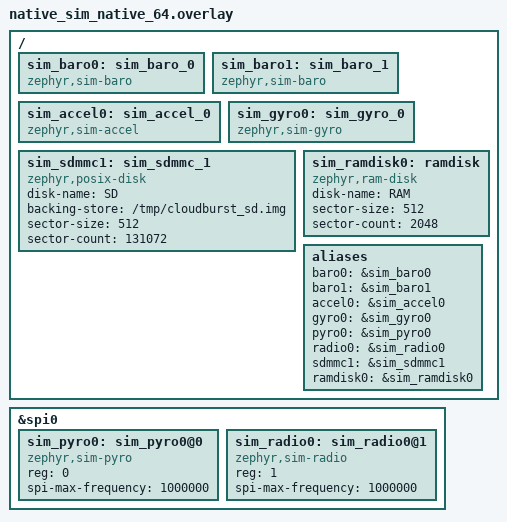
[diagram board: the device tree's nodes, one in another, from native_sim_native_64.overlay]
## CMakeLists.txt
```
# SPDX-License-Identifier: Apache-2.0

cmake_minimum_required(VERSION 3.20.0)

list(APPEND DTS_ROOT ${CMAKE_CURRENT_SOURCE_DIR})

set(BOARD_ROOT ${CMAKE_CURRENT_LIST_DIR}/..)

set(ZEPHYR_EXTRA_MODULES ${CMAKE_CURRENT_LIST_DIR}/..)

# Compatible boards for this app
set(COMPATIBLE_BOARDS
    ubcrocket_polarity
    native_sim/native/64
    native_sim
)

if(NOT BOARD IN_LIST COMPATIBLE_BOARDS)
    message(WARNING
        "Board '${BOARD}' is not listed as compatible with this application.\n"
        "Compatible boards: ${COMPATIBLE_BOARDS}\n"
        "Build may fail or behave unexpectedly.\n"
        "To add compatibility for this board, add it to the COMPATIBLE_BOARDS list in CMakeLists.txt.")
endif()

find_package(Zephyr REQUIRED HINTS $ENV{ZEPHYR_BASE})
project(cloudburst)

# Include nanopb for protobuf support
list(APPEND CMAKE_MODULE_PATH ${ZEPHYR_BASE}/modules/nanopb)
include(nanopb)

# Generate protobuf sources from falcon-protos
set(FALCON_PROTOS_DIR ${CMAKE_CURRENT_LIST_DIR}/../../modules/falcon-protos)
zephyr_nanopb_sources(app ${FALCON_PROTOS_DIR}/TelemetryPacket.proto)
zephyr_nanopb_sources(app ${FALCON_PROTOS_DIR}/GroundCommand.proto)

# LwGPS NMEA parser library
set(LWGPS_DIR ${CMAKE_CURRENT_LIST_DIR}/../../modules/lwgps)

target_sources(app PRIVATE
  src/main.c
  src/data.c
  src/sensors/imu_thread.c
  src/logger_thread.c
  src/sensors/baro_thread.c
  src/state_machine/state_machine.c
  src/state_machine/state_machine_common.c
  src/state_machine/states/standby.c
  src/state_machine/states/ascent.c
  src/state_machine/states/mach_lock.c
  src/state_machine/states/drogue_descent.c
  src/state_machine/states/main_descent.c
  src/state_machine/states/landed.c
  src/pyro/pyro_thread.c
  src/radio/radio_thread.c
  src/radio/gnss_spi.c
  src/radio/command_thread.c
  src/radio/rfd900x_at.c
  src/radio/rfd900x.c
  src/camera/vtx_power.c
  src/camera/runcam.c
  src/gps/gps_thread.c
  ${LWGPS_DIR}/lwgps/src/lwgps/lwgps.c
)

target_include_directories(app PRIVATE
  src
  src/state_machine
  src/gps
  ${LWGPS_DIR}/lwgps/src/include
)

if(DEFINED DATA_FILE)
  zephyr_compile_definitions(DATA_FILE="${DATA_FILE}")
endif()
```

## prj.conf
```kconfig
# Enable simulated sensors for native_sim
CONFIG_SIM_BARO=y
CONFIG_SIM_ACCEL=y
CONFIG_SIM_GYRO=y
CONFIG_SIM_PYRO=y
CONFIG_SIM_RADIO=y
CONFIG_SIM_SDMMC=y

# Enable GPIO support
CONFIG_GPIO=y

# Enable sensor subsystem
CONFIG_SENSOR=y

# Enable SPI support
CONFIG_SPI=y

# Enable C++ support
CONFIG_CPP=y

# Enable SMF (state machine framework)
CONFIG_SMF=y

# Enable BMI08X sensor driver
CONFIG_BMI08X=y
CONFIG_BMI08X_ACCEL_TRIGGER_NONE=y
CONFIG_BMI08X_GYRO_TRIGGER_NONE=y

# Enable MS5607 and MS5611 barometer drivers
CONFIG_MS5607=y
CONFIG_MS5611=y

# Enable SDMMC disk driver and hardware flow control
CONFIG_DISK_DRIVER_SDMMC=y
CONFIG_SDMMC_STM32_HWFC=y

# Enable disk access API
CONFIG_DISK_ACCESS=y

# Enable file system support
CONFIG_FILE_SYSTEM=y
CONFIG_FAT_FILESYSTEM_ELM=y
CONFIG_FS_FATFS_LFN=y

# Set main thread stack size
CONFIG_MAIN_STACK_SIZE=2048

# Enable sensor asynchronous API
CONFIG_SENSOR_ASYNC_API=y

# Enable debugging features (for development only)
CONFIG_PRINTK=y
CONFIG_CBPRINTF_FP_SUPPORT=y
CONFIG_LOG=y
CONFIG_LOG_MODE_IMMEDIATE=y
CONFIG_SENSOR_LOG_LEVEL_DBG=n
CONFIG_SPI_LOG_LEVEL_DBG=n
CONFIG_GPIO_LOG_LEVEL_DBG=n
CONFIG_BOOT_BANNER=y
CONFIG_ASSERT=n
CONFIG_DEBUG=y
CONFIG_NO_OPTIMIZATIONS=y

# Enable thread debugging features
CONFIG_DEBUG_THREAD_INFO=y
CONFIG_THREAD_MONITOR=y
CONFIG_THREAD_NAME=y
CONFIG_THREAD_STACK_INFO=n
CONFIG_STACK_SENTINEL=y

# Enable nanopb for protobuf support
CONFIG_NANOPB=y

# Enable CRC for packet integrity checking
CONFIG_CRC=y

# Enable COBS for packet framing
CONFIG_COBS=y
```

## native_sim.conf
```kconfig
# Disable embedded filesystems
CONFIG_FILE_SYSTEM_LITTLEFS=n
CONFIG_FILE_SYSTEM_FATFS=n

# Enable host filesystem
CONFIG_FILE_SYSTEM=y
CONFIG_FS_POSIX=y
CONFIG_POSIX_FS=y

# Enable simulated sensors for native_sim
CONFIG_SIM_BARO=y
CONFIG_SIM_ACCEL=y
CONFIG_SIM_GYRO=y
CONFIG_SIM_PYRO=y
CONFIG_SIM_SDMMC=y

# Enable fake sensors for native_sim
CONFIG_EMUL=y
CONFIG_SPI_EMUL=y
CONFIG_SENSOR_SHELL=y

# Enable the random number generator for native_sim
CONFIG_ENTROPY_GENERATOR=y

# Enable RAM disk driver for native_sim
CONFIG_DISK_DRIVER_RAM=y
```

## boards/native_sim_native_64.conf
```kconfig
CONFIG_FILE_SYSTEM=y
CONFIG_FILE_SYSTEM_SHELL=y

# Disable SD card specific features
CONFIG_FAT_FILESYSTEM_ELM=n
CONFIG_DISK_DRIVER_SDMMC=n

# Enable simulated sensors for native_sim
CONFIG_SIM_BARO=y
CONFIG_SIM_ACCEL=y
CONFIG_SIM_GYRO=y
CONFIG_SIM_PYRO=y
CONFIG_SIM_SDMMC=y

# Enable fake sensors for native_sim
CONFIG_EMUL=y
CONFIG_SPI_EMUL=y
CONFIG_SENSOR_SHELL=y

# Enable the random number generator for native_sim
CONFIG_ENTROPY_GENERATOR=y

# Enable RAM disk driver for native_sim
CONFIG_DISK_DRIVER_RAM=y
```

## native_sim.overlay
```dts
/ {
    sim_baro0: sim_baro_0 {
        compatible = "zephyr,sim-baro";
        status = "okay";
    };

    sim_baro1: sim_baro_1 {
        compatible = "zephyr,sim-baro";
        status = "okay";
    };

    sim_accel0: sim_accel_0 {
        compatible = "zephyr,sim-accel";
        status = "okay";
    };

    sim_gyro0: sim_gyro_0 {
        compatible = "zephyr,sim-gyro";
        status = "okay";
    };

    sim_sdmmc1: sim_sdmmc_1 {
        compatible = "zephyr,posix-disk";
        status = "okay";
        disk-name = "SD";
        backing-store = "/tmp/cloudburst_sd.img";
        sector-size = <512>;
        sector-count = <131072>; /* 64 MB */
    };

    sim_ramdisk0: ramdisk {
        compatible = "zephyr,ram-disk";
        disk-name = "RAM";
        sector-size = <512>;
        sector-count = <2048>; /* 1 MB */
    };

    aliases {
        baro0 = &sim_baro0;
        baro1 = &sim_baro1;
        accel0 = &sim_accel0;
        gyro0 = &sim_gyro0;
        pyro0 = &sim_pyro0;
        sdmmc1 = &sim_sdmmc1;
        ramdisk0 = &sim_ramdisk0;
    };
};

&spi0 {
    status = "okay";

    sim_pyro0: sim_pyro0@0 {
        compatible = "zephyr,sim-pyro";
        reg = <0>;
        spi-max-frequency = <1000000>;
        status = "okay";
    };
};
```

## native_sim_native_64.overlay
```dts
/ {
    sim_baro0: sim_baro_0 {
        compatible = "zephyr,sim-baro";
        status = "okay";
    };

    sim_baro1: sim_baro_1 {
        compatible = "zephyr,sim-baro";
        status = "okay";
    };

    sim_accel0: sim_accel_0 {
        compatible = "zephyr,sim-accel";
        status = "okay";
    };

    sim_gyro0: sim_gyro_0 {
        compatible = "zephyr,sim-gyro";
        status = "okay";
    };

    sim_sdmmc1: sim_sdmmc_1 {
        compatible = "zephyr,posix-disk";
        status = "okay";
        disk-name = "SD";
        backing-store = "/tmp/cloudburst_sd.img";
        sector-size = <512>;
        sector-count = <131072>; /* 64 MB */
    };

    sim_ramdisk0: ramdisk {
        compatible = "zephyr,ram-disk";
        disk-name = "RAM";
        sector-size = <512>;
        sector-count = <2048>; /* 1 MB */
    };

    aliases {
        baro0 = &sim_baro0;
        baro1 = &sim_baro1;
        accel0 = &sim_accel0;
        gyro0 = &sim_gyro0;
        pyro0 = &sim_pyro0;
        radio0 = &sim_radio0;
        sdmmc1 = &sim_sdmmc1;
        ramdisk0 = &sim_ramdisk0;
    };
};

&spi0 {
    status = "okay";

    sim_pyro0: sim_pyro0@0 {
        compatible = "zephyr,sim-pyro";
        reg = <0>;
        spi-max-frequency = <1000000>;
        status = "okay";
    };

    sim_radio0: sim_radio0@1 {
        compatible = "zephyr,sim-radio";
        reg = <1>;
        spi-max-frequency = <1000000>;
        status = "okay";
    };
};
```

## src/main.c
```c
#include <zephyr/kernel.h>
#include <zephyr/device.h>
#include <zephyr/devicetree.h>
#include <zephyr/drivers/sensor.h>
#include <zephyr/logging/log.h>
#include "sensors/imu_thread.h"
#include "sensors/baro_thread.h"
#include "logger_thread.h"
#include "state_machine/state_machine.h"
#include "pyro/pyro_thread.h"
#include "radio/radio_thread.h"
#include "radio/command_thread.h"
#include "gps/gps_thread.h"
#include "data.h"

LOG_MODULE_REGISTER(falcon_main, LOG_LEVEL_INF);

int main(void)
{
    LOG_INF("Falcon application started");

    // Start the threads
    start_imu_thread();
    start_logger_thread();
    start_baro_thread();
    start_pyro_thread();
    start_state_machine_thread();
    start_radio_thread();
    start_gps_thread();
    start_command_threads();

    return 0;
}
```

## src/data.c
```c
#include <zephyr/kernel.h>
#include <zephyr/logging/log.h>
#include "data.h"

LOG_MODULE_REGISTER(data, LOG_LEVEL_INF);

// Global instances
struct imu_data g_imu_data;
struct baro_data g_baro_data;
struct state_data g_state_data;
struct pyro_data g_pyro_data;
struct gps_data g_gps_data;
struct camera_data g_camera_data;

// Mutexes for thread safety
K_MUTEX_DEFINE(imu_mutex);
K_MUTEX_DEFINE(baro_mutex);
K_MUTEX_DEFINE(state_mutex);
K_MUTEX_DEFINE(pyro_data_mutex);
K_MUTEX_DEFINE(gps_mutex);
K_MUTEX_DEFINE(camera_mutex);

// Setter functions
void set_imu_data(const struct imu_data *src)
{
    k_mutex_lock(&imu_mutex, K_FOREVER);
    g_imu_data = *src;
    k_mutex_unlock(&imu_mutex);
}

void set_baro_data(const struct baro_data *src)
{
    k_mutex_lock(&baro_mutex, K_FOREVER);
    g_baro_data = *src;
    k_mutex_unlock(&baro_mutex);
}

// Getter functions
void get_imu_data(struct imu_data *dst)
{
    k_mutex_lock(&imu_mutex, K_FOREVER);
    *dst = g_imu_data;
    k_mutex_unlock(&imu_mutex);
}

void get_baro_data(struct baro_data *dst)
{
    k_mutex_lock(&baro_mutex, K_FOREVER);
    *dst = g_baro_data;
    k_mutex_unlock(&baro_mutex);
}

void set_state_data(const struct state_data *src)
{
    k_mutex_lock(&state_mutex, K_FOREVER);
    g_state_data = *src;
    k_mutex_unlock(&state_mutex);
}

void get_state_data(struct state_data *dst)
{
    k_mutex_lock(&state_mutex, K_FOREVER);
    *dst = g_state_data;
    k_mutex_unlock(&state_mutex);
}

void set_pyro_data(const struct pyro_data *src)
{
    k_mutex_lock(&pyro_data_mutex, K_FOREVER);

    // Log changes to pyro flags
    if (src->drogue_fire_requested != g_pyro_data.drogue_fire_requested) {
        LOG_INF("Pyro: drogue_fire_requested -> %d", src->drogue_fire_requested);
    }
    if (src->main_fire_requested != g_pyro_data.main_fire_requested) {
        LOG_INF("Pyro: main_fire_requested -> %d", src->main_fire_requested);
    }
    if (src->drogue_fire_ack != g_pyro_data.drogue_fire_ack) {
        LOG_INF("Pyro: drogue_fire_ack -> %d", src->drogue_fire_ack);
    }
    if (src->main_fire_ack != g_pyro_data.main_fire_ack) {
        LOG_INF("Pyro: main_fire_ack -> %d", src->main_fire_ack);
    }
    if (src->drogue_fired != g_pyro_data.drogue_fired) {
        LOG_INF("Pyro: drogue_fired -> %d", src->drogue_fired);
    }
    if (src->main_fired != g_pyro_data.main_fired) {
        LOG_INF("Pyro: main_fired -> %d", src->main_fired);
    }
    if (src->drogue_fail != g_pyro_data.drogue_fail) {
        LOG_ERR("Pyro: drogue_fail -> %d", src->drogue_fail);
    }
    if (src->main_fail != g_pyro_data.main_fail) {
        LOG_ERR("Pyro: main_fail -> %d", src->main_fail);
    }
    if (src->drogue_cont_ok != g_pyro_data.drogue_cont_ok) {
        LOG_INF("Pyro: drogue_cont_ok -> %d", src->drogue_cont_ok);
    }
    if (src->main_cont_ok != g_pyro_data.main_cont_ok) {
        LOG_INF("Pyro: main_cont_ok -> %d", src->main_cont_ok);
    }

    g_pyro_data = *src;
    k_mutex_unlock(&pyro_data_mutex);
}

void get_pyro_data(struct pyro_data *dst)
{
    k_mutex_lock(&pyro_data_mutex, K_FOREVER);
    *dst = g_pyro_data;
    k_mutex_unlock(&pyro_data_mutex);
}

void set_gps_data(const struct gps_data *src)
{
    k_mutex_lock(&gps_mutex, K_FOREVER);
    g_gps_data = *src;
    k_mutex_unlock(&gps_mutex);
}

void get_gps_data(struct gps_data *dst)
{
    k_mutex_lock(&gps_mutex, K_FOREVER);
    *dst = g_gps_data;
    k_mutex_unlock(&gps_mutex);
}

void set_camera_data(const struct camera_data *src)
{
    k_mutex_lock(&camera_mutex, K_FOREVER);

    if (src->vtx_power_on != g_camera_data.vtx_power_on) {
        LOG_INF("Camera: vtx_power_on -> %d", src->vtx_power_on);
    }
    if (src->recording != g_camera_data.recording) {
        LOG_INF("Camera: recording -> %d", src->recording);
    }

    g_camera_data = *src;
    k_mutex_unlock(&camera_mutex);
}

void get_camera_data(struct camera_data *dst)
{
    k_mutex_lock(&camera_mutex, K_FOREVER);
    *dst = g_camera_data;
    k_mutex_unlock(&camera_mutex);
}
```

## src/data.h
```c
#ifndef DATA_H
#define DATA_H

#include <stdint.h>
#include <stdbool.h>

typedef enum {
    FLIGHT_STATE_STANDBY = 0,
    FLIGHT_STATE_ASCENT,
    FLIGHT_STATE_MACH_LOCK,
    FLIGHT_STATE_DROGUE_DESCENT,
    FLIGHT_STATE_MAIN_DESCENT,
    FLIGHT_STATE_LANDED,
} flight_state_id_t;

// Data structures for sensor data
struct imu_data {
    float accel[3];    // Acceleration in m/s²
    float gyro[3];     // Angular velocity in rad/s
    int64_t timestamp; // Timestamp in milliseconds
};

// Per-barometer sensor data
struct baro_sensor_data {
    float pressure;    // Pressure in Pa
    float temperature; // Temperature in °C
    float altitude;    // Altitude in meters (from pressure + temp)
    float nis;         // Normalized innovation squared
    uint8_t faults;    // Accumulated fault count
    bool healthy;      // Health status (accepted/rejected)
};

// Combined barometer data (shared with other threads)
struct baro_data {
    struct baro_sensor_data baro0; // Barometer 0
    struct baro_sensor_data baro1; // Barometer 1

    float altitude;     // Kalman-filtered altitude estimate in meters (absolute)
    float altitude_agl; // Kalman-filtered altitude AGL (relative to ground) in meters
    float alt_variance; // Kalman filter variance (P)
    float velocity;     // Vertical velocity estimate (m/s)
    float vel_variance; // Velocity variance (P11)

    int64_t timestamp; // Timestamp in milliseconds
};

struct state_data {
    flight_state_id_t state;
    float ground_altitude;
    bool ground_calibrated;
    int64_t timestamp;
};

struct pyro_data {
    uint8_t status_byte;
    int64_t timestamp;
    bool drogue_fired;
    bool main_fired;
    bool drogue_fail;
    bool main_fail;
    bool drogue_cont_ok;
    bool main_cont_ok;
    bool drogue_fire_ack;
    bool main_fire_ack;
    bool drogue_fire_requested;
    bool main_fire_requested;
};

struct gps_data {
    float latitude;   // Degrees
    float longitude;  // Degrees
    float altitude;   // Altitude in meters
    float speed;      // Speed in knots
    uint8_t sats;     // Satellites in use
    uint8_t fix;      // Fix quality
    int64_t timestamp;
};

// VTX/RunCam status (shared between command executor, state machine and radio)
struct camera_data {
    bool vtx_power_on; // VTX/RunCam power switch state
    bool recording;    // RunCam recording state (optimistic, no protocol ack)
    int64_t timestamp;
};

// Global instances
extern struct imu_data g_imu_data;
extern struct baro_data g_baro_data;
extern struct state_data g_state_data;
extern struct pyro_data g_pyro_data;
extern struct gps_data g_gps_data;
extern struct camera_data g_camera_data;

// Getters and setters
void set_imu_data(const struct imu_data *src);
void get_imu_data(struct imu_data *dst);

void set_baro_data(const struct baro_data *src);
void get_baro_data(struct baro_data *dst);

void set_state_data(const struct state_data *src);
void get_state_data(struct state_data *dst);

void set_pyro_data(const struct pyro_data *src);
void get_pyro_data(struct pyro_data *dst);

void set_gps_data(const struct gps_data *src);
void get_gps_data(struct gps_data *dst);

void set_camera_data(const struct camera_data *src);
void get_camera_data(struct camera_data *dst);

#endif
```

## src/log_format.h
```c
#ifndef LOG_FORMAT_H
#define LOG_FORMAT_H

#include "data.h"
#include <stdint.h>

struct log_frame {
    int64_t log_timestamp;

    struct imu_data imu;
    struct baro_data baro;
    struct state_data state;
    struct pyro_data pyro;
    struct gps_data gps;
};

#endif
```

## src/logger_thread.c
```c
#include <zephyr/kernel.h>
#include <zephyr/sys/printk.h>
#include <zephyr/logging/log.h>
#include <zephyr/device.h>
#include <stdio.h>
#include <string.h>
#include "data.h"
#include "log_format.h"

#ifndef CONFIG_BOARD_NATIVE_SIM
#include <zephyr/storage/disk_access.h>
#include <zephyr/fs/fs.h>
#include <ff.h>
#endif

LOG_MODULE_REGISTER(logger_thread, LOG_LEVEL_INF);

#define LOGGER_THREAD_STACK_SIZE 2048
#define LOGGER_THREAD_PRIORITY 7
#define LOGGER_THREAD_PERIOD_MS 50
#define LOGGER_SYNC_PERIOD_MS 500

#ifdef CONFIG_BOARD_NATIVE_SIM
// Use standard POSIX file I/O for native_sim
#include <unistd.h>
#include <fcntl.h>
#include <dirent.h>
#include <sys/stat.h>

#define MOUNT_POINT "/tmp/zephyr_logs"
static FILE *log_file_ptr = NULL;

#else
// Use Zephyr FS API for real hardware
#define SDMMC_NODE DT_ALIAS(sdmmc1)
#define DISK_DRIVE_NAME DT_PROP(SDMMC_NODE, disk_name)
#define MOUNT_POINT "/" DISK_DRIVE_NAME ":"

static FATFS fat_fs;
static struct fs_mount_t fatfs_mnt = {
    .type = FS_FATFS, .mnt_point = MOUNT_POINT, .fs_data = &fat_fs};

static struct fs_file_t log_file;
#endif

K_THREAD_STACK_DEFINE(logger_stack, LOGGER_THREAD_STACK_SIZE);
static struct k_thread logger_thread;

static char log_file_name[128];

static int mount_filesystem(void)
{
#ifdef CONFIG_BOARD_NATIVE_SIM
    // Create directory if it doesn't exist
    struct stat st = {0};
    if (stat(MOUNT_POINT, &st) == -1) {
        mkdir(MOUNT_POINT, 0755);
    }
    LOG_INF("Using POSIX filesystem at %s", MOUNT_POINT);
    return 0;
#else
    int ret;

    // Initialize the SDMMC disk
    ret = disk_access_ioctl(DISK_DRIVE_NAME, DISK_IOCTL_CTRL_INIT, NULL);
    if (ret < 0) {
        LOG_ERR("Disk access initialization failed: %d", ret);
        return ret;
    }

    // Mount the FATFS file system
    ret = fs_mount(&fatfs_mnt);
    if (ret == 0) {
        LOG_INF("File system mounted at %s", MOUNT_POINT);
    } else {
        LOG_ERR("File system mount failed: %d", ret);
    }
    return ret;
#endif
}

static int write_csv_header(void)
{
    const char *header = "Log_Timestamp(ms),"
                         "IMU_Timestamp(ms),Accel_X(m/s^2),Accel_Y(m/s^2),Accel_Z(m/s^2),"
                         "Gyro_X(rad/s),Gyro_Y(rad/s),Gyro_Z(rad/s),"
                         "Baro_Timestamp(ms),"
                         "Baro0_Pressure(Pa),Baro0_Temperature(C),Baro0_Altitude(m),Baro0_NIS,"
                         "Baro0_Faults,Baro0_Healthy,"
                         "Baro1_Pressure(Pa),Baro1_Temperature(C),Baro1_Altitude(m),Baro1_NIS,"
                         "Baro1_Faults,Baro1_Healthy,"
                         "KF_Altitude(m),KF_Altitude_AGL(m),KF_AltVar,KF_Velocity(m/s),KF_VelVar,"
                         "State,State_Ground_Altitude(m),State_Timestamp(ms),"
                         "Pyro_Status,Pyro_Timestamp(ms),"
                         "Drogue_Fired,Main_Fired,Drogue_Fail,Main_Fail,"
                         "Drogue_Cont_OK,Main_Cont_OK,Drogue_Fire_ACK,Main_Fire_ACK,"
                         "Drogue_Fire_Requested,Main_Fire_Requested,"
                         "GPS_Timestamp(ms),GPS_Lat(deg),GPS_Lon(deg),"
                         "GPS_Alt(m),GPS_Speed(kn),GPS_Sats,GPS_Fix\n";
#ifdef CONFIG_BOARD_NATIVE_SIM
    size_t written = fwrite(header, 1, strlen(header), log_file_ptr);
    if (written != strlen(header)) {
        LOG_ERR("Failed to write header");
        return -1;
    }
    fflush(log_file_ptr);
    return 0;
#else
    int ret = fs_write(&log_file, header, strlen(header));
    if (ret < 0) {
        LOG_ERR("Failed to write header to log file: %d", ret);
        return ret;
    }

    ret = fs_sync(&log_file);
    if (ret < 0) {
        LOG_ERR("Failed to sync log file after writing header: %d", ret);
        return ret;
    }
    return 0;
#endif
}

static int create_new_log_file(void)
{
    int file_count = 0;

#ifdef CONFIG_BOARD_NATIVE_SIM
    DIR *dir = opendir(MOUNT_POINT);
    if (dir) {
        struct dirent *entry;
        struct stat st;
        char filepath[256];

        while ((entry = readdir(dir)) != NULL) {
            // Skip "." and ".." entries
            if (strcmp(entry->d_name, ".") == 0 || strcmp(entry->d_name, "..") == 0) {
                continue;
            }

            // Build full path and check if it's a regular file
            snprintf(filepath, sizeof(filepath), "%s/%s", MOUNT_POINT, entry->d_name);
            if (stat(filepath, &st) == 0 && S_ISREG(st.st_mode)) {
                file_count++;
            }
        }
        closedir(dir);
    }

    snprintf(log_file_name, sizeof(log_file_name), "%s/log_%d.csv", MOUNT_POINT, file_count);

    log_file_ptr = fopen(log_file_name, "w");
    if (!log_file_ptr) {
        LOG_ERR("Failed to open log file: %s", log_file_name);
        return -1;
    }

    LOG_INF("Log file created: %s", log_file_name);
#else
    int ret;
    struct fs_dir_t dir;
    struct fs_dirent entry;

    fs_dir_t_init(&dir);
    ret = fs_opendir(&dir, MOUNT_POINT);
    if (ret < 0) {
        LOG_ERR("Failed to open directory: %d", ret);
        return ret;
    }

    while (fs_readdir(&dir, &entry) == 0 && entry.name[0] != '\0') {
        if (entry.type == FS_DIR_ENTRY_FILE) {
            file_count++;
        }
    }
    fs_closedir(&dir);

    snprintf(log_file_name, sizeof(log_file_name), MOUNT_POINT "/log_%d.csv", file_count);

    fs_file_t_init(&log_file);
    ret = fs_open(&log_file, log_file_name, FS_O_CREATE | FS_O_APPEND | FS_O_WRITE);
    if (ret < 0) {
        LOG_ERR("Failed to open log file: %d", ret);
        return ret;
    }

    LOG_INF("Log file created: %s", log_file_name);
#endif

    return write_csv_header();
}

static int format_log_entry(const struct log_frame *frame, char *buffer, size_t buffer_size)
{
    return snprintf(
        buffer, buffer_size,
        "%lld,%lld,%.3f,%.3f,%.3f,%.3f,%.3f,%.3f,%lld," // Log_Timestamp, IMU_Timestamp,
                                                        // Accel_X/Y/Z, Gyro_X/Y/Z, Baro_Timestamp
        "%.3f,%.3f,%.3f,%.3f,%u,%d," // Baro0_Pressure, Baro0_Temperature, Baro0_Altitude,
                                     // Baro0_NIS, Baro0_Faults, Baro0_Healthy
        "%.3f,%.3f,%.3f,%.3f,%u,%d," // Baro1_Pressure, Baro1_Temperature, Baro1_Altitude,
                                     // Baro1_NIS, Baro1_Faults, Baro1_Healthy
        "%.3f,%.3f,%.3f,%.3f,%.3f,%d,%.3f,%lld," // KF_Altitude, KF_Altitude_AGL, KF_AltVar,
                                                 // KF_Velocity, KF_VelVar, State,
                                                 // State_Ground_Altitude, State_Timestamp
        "%u,%lld,%d,%d,%d,%d,%d,%d,%d,%d,%d,%d," // Pyro_Status, Pyro_Timestamp, Drogue_Fired,
                                                 // Main_Fired, Drogue_Fail, Main_Fail,
                                                 // Drogue_Cont_OK, Main_Cont_OK, Drogue_Fire_ACK,
                                                 // Main_Fire_ACK, Drogue_Fire_Requested,
                                                 // Main_Fire_Requested
        "%lld,%.6f,%.6f,%.1f,%.1f,%u,%u\n", // GPS_Timestamp, GPS_Lat, GPS_Lon, GPS_Alt, GPS_Speed,
                                            // GPS_Sats, GPS_Fix
        frame->log_timestamp, frame->imu.timestamp, (double)frame->imu.accel[0],
        (double)frame->imu.accel[1], (double)frame->imu.accel[2], (double)frame->imu.gyro[0],
        (double)frame->imu.gyro[1], (double)frame->imu.gyro[2], frame->baro.timestamp,
        (double)frame->baro.baro0.pressure, (double)frame->baro.baro0.temperature,
        (double)frame->baro.baro0.altitude, (double)frame->baro.baro0.nis,
        (unsigned int)frame->baro.baro0.faults, frame->baro.baro0.healthy ? 1 : 0,
        (double)frame->baro.baro1.pressure, (double)frame->baro.baro1.temperature,
        (double)frame->baro.baro1.altitude, (double)frame->baro.baro1.nis,
        (unsigned int)frame->baro.baro1.faults, frame->baro.baro1.healthy ? 1 : 0,
        (double)frame->baro.altitude, (double)frame->baro.altitude_agl,
        (double)frame->baro.alt_variance, (double)frame->baro.velocity,
        (double)frame->baro.vel_variance, (int)frame->state.state,
        (double)frame->state.ground_altitude, frame->state.timestamp,
        (unsigned int)frame->pyro.status_byte, frame->pyro.timestamp,
        frame->pyro.drogue_fired ? 1 : 0, frame->pyro.main_fired ? 1 : 0,
        frame->pyro.drogue_fail ? 1 : 0, frame->pyro.main_fail ? 1 : 0,
        frame->pyro.drogue_cont_ok ? 1 : 0, frame->pyro.main_cont_ok ? 1 : 0,
        frame->pyro.drogue_fire_ack ? 1 : 0, frame->pyro.main_fire_ack ? 1 : 0,
        frame->pyro.drogue_fire_requested ? 1 : 0, frame->pyro.main_fire_requested ? 1 : 0,
        frame->gps.timestamp, (double)frame->gps.latitude, (double)frame->gps.longitude,
        (double)frame->gps.altitude, (double)frame->gps.speed, (unsigned int)frame->gps.sats,
        (unsigned int)frame->gps.fix);
}

static void write_log_frame_to_file(const struct log_frame *frame)
{
    char log_entry[512];
    int len = format_log_entry(frame, log_entry, sizeof(log_entry));

    if (len >= sizeof(log_entry)) {
        LOG_ERR("Log buffer size: %zu, Required size: %d", sizeof(log_entry), len);
        return;
    } else if (len < 0) {
        LOG_ERR("Failed to format log entry: %d", len);
        return;
    }

#ifdef CONFIG_BOARD_NATIVE_SIM
    size_t written = fwrite(log_entry, 1, len, log_file_ptr);
    if (written != (size_t)len) {
        LOG_ERR("Failed to write to log file");
    }
#else
    int ret = fs_write(&log_file, log_entry, len);
    if (ret < 0) {
        LOG_ERR("Failed to write to log file: %d", ret);
    }
#endif
}

static void logger_thread_fn(void *p1, void *p2, void *p3)
{
    struct log_frame frame;

    if (mount_filesystem() < 0) {
        return;
    }

    if (create_new_log_file() < 0) {
        return;
    }

    int64_t last_sync_ms = k_uptime_get();

    while (1) {
        frame.log_timestamp = k_uptime_get();
        get_imu_data(&frame.imu);
        get_baro_data(&frame.baro);
        get_state_data(&frame.state);
        get_pyro_data(&frame.pyro);
        get_gps_data(&frame.gps);

        write_log_frame_to_file(&frame);

        if ((frame.log_timestamp - last_sync_ms) >= LOGGER_SYNC_PERIOD_MS) {
#ifdef CONFIG_BOARD_NATIVE_SIM
            fflush(log_file_ptr);
#else
            int ret = fs_sync(&log_file);
            if (ret < 0) {
                LOG_ERR("Failed to sync log file: %d", ret);
            }
#endif
            last_sync_ms = frame.log_timestamp;
        }

        k_sleep(K_MSEC(LOGGER_THREAD_PERIOD_MS));
    }
}

void start_logger_thread()
{
    k_thread_create(&logger_thread, logger_stack, K_THREAD_STACK_SIZEOF(logger_stack),
                    logger_thread_fn, NULL, NULL, NULL, LOGGER_THREAD_PRIORITY, 0, K_NO_WAIT);
}
```

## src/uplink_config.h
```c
#ifndef UPLINK_CONFIG_H
#define UPLINK_CONFIG_H

/*
 * Two-way radio uplink: NOT-YET-CONFIRMED constants, collected in one place.
 *
 * Values below are PLACEHOLDERS pending confirmation from the team unless
 * marked CONFIRMED. When a real value is known, changing it here is the
 * only edit needed.
 *
 * Confirmed by the hardware team (live in the devicetree,
 * boards/ubcrocket/polarity/ubcrocket_polarity.dts):
 *   - vtx-pwr GPIO: PD6 (active level assumed high)
 *   - runcam-uart port: UART4 on PD1 (TX) / PD0 (RX)
 */

/*
 * CONFIRMED (2026-07-26, ulysses-gnss-radio Core/Inc/protocol_config.h):
 * SPI opcode for reading received radio bytes from the ulysses-gnss-radio
 * board -- CMD_RADIO_RX_FIFO, oldest message first so uplinked commands are
 * processed in the order the ground sent them (0x01 is the LIFO variant).
 * Framing mirrors the GPS read (0x05): [CMD:1][DUMMY:4][PAYLOAD:256].
 * The GNSS board splits the radio UART stream on 0x00, strips the
 * terminator, and zero-pads each message into a 256-byte queue slot, so
 * the payload holds one COBS-encoded frame (protobuf + CRC16) whose zero
 * padding acts as the delimiter; all-zero when nothing is pending.
 */
#define UPLINK_SPI_CMD_RADIO_RX 0x02

/*
 * PLACEHOLDER: RunCam UART command set -- waiting on David to confirm the
 * exact protocol. Values below follow the public RunCam Device Protocol:
 * frame = [0xCC][command id][payload...][CRC8 poly 0xD5 over all prior bytes].
 * Note the protocol defines no response for CAMERA_CONTROL, so recording
 * state is updated optimistically until an ack mechanism is confirmed.
 *
 * DORMANT: the RunCam has auto-recording enabled, so nothing currently
 * sends these frames -- recording follows the VTX power rail. The runcam
 * module is kept for when the protobufs are reworked to carry RunCam
 * commands.
 */
#define RUNCAM_PROTO_HEADER 0xCC
#define RUNCAM_CMD_CAMERA_CONTROL 0x01
#define RUNCAM_ACTION_START_RECORDING 0x03
#define RUNCAM_ACTION_STOP_RECORDING 0x04
#define RUNCAM_CRC8_POLY 0xD5

/*
 * RFD900x remote reconfiguration (checklist Phase 4).
 *
 * CONFIRMED (2026-07-30): reconfiguration runs as AT passthrough over the
 * SPI link to the ulysses-gnss-radio board, which owns the modem serial
 * (UART5, 57600 8N1). The direct-UART path (USART2/PA2-PA3) stays DISABLED
 * per the hardware team -- FALCON driving PA2 contends with that board.
 * See gnss_spi.h for the opcode family and rfd900x.c for the transport;
 * the AT session engine itself is transport-agnostic.
 *
 * Timing follows the SiK/RFD900x AT spec: 1 s of serial silence before
 * "+++" (no CR/LF), and roughly 1 s more before the modem answers "OK".
 * The #ifndef guards let the unit tests shrink the timing so the
 * timeout-path tests run fast.
 */
#ifndef RFD_AT_GUARD_TIME_MS
#define RFD_AT_GUARD_TIME_MS 1100
#endif
#ifndef RFD_AT_ENTER_TIMEOUT_MS
#define RFD_AT_ENTER_TIMEOUT_MS 2500
#endif
#ifndef RFD_AT_RESPONSE_TIMEOUT_MS
#define RFD_AT_RESPONSE_TIMEOUT_MS 1500
#endif

/*
 * PLACEHOLDER: RfdConfig validation bounds -- confirm against the modem's
 * actual firmware limits with the team. Out-of-range values are rejected
 * before the AT session starts so they can never reach the modem.
 * Frequency band is the RFD900x 902-928 MHz ISM band; NETID/power/air
 * speed/channel bounds follow the SiK S-register documentation.
 */
#define RFD_FREQ_KHZ_MIN 902000
#define RFD_FREQ_KHZ_MAX 928000
#define RFD_NET_ID_MAX 499
#define RFD_TX_POWER_DBM_MAX 30
#define RFD_AIR_SPEED_MIN 4
#define RFD_AIR_SPEED_MAX 750
#define RFD_NUM_CHANNELS_MIN 1
#define RFD_NUM_CHANNELS_MAX 50

#endif /* UPLINK_CONFIG_H */
```
